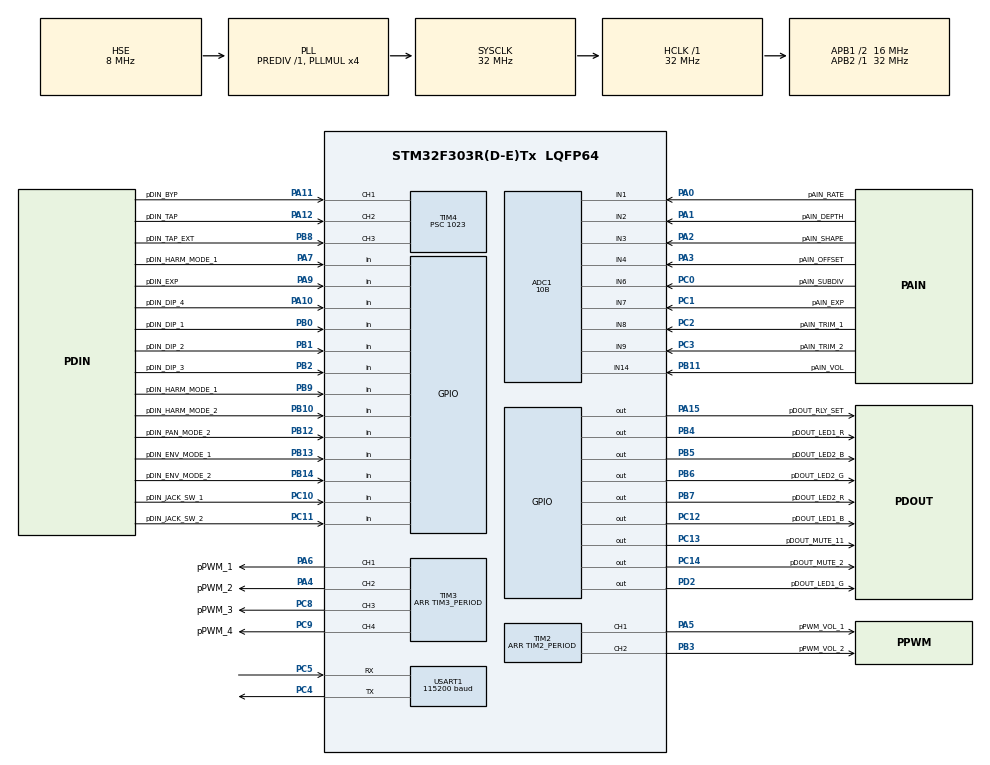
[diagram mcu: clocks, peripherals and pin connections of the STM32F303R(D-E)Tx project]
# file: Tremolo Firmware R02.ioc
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ADC1.AWD1ITMode=ENABLE
ADC1.Channel-0\#ChannelRegularConversion=ADC_CHANNEL_1
ADC1.ClockPrescaler=ADC_CLOCK_SYNC_PCLK_DIV1
ADC1.ContinuousConvMode=ENABLE
ADC1.DMAContinuousRequests=ENABLE
ADC1.EOCSelection=ADC_EOC_SEQ_CONV
ADC1.EnableAnalogWatchDog1=true
ADC1.EnableInjectedConversion=DISABLE
ADC1.ExternalTrigConv=ADC_SOFTWARE_START
ADC1.Mode=ADC_MODE_INDEPENDENT
ADC1.NbrOfConversion=1
ADC1.NbrOfConversionFlag=1
ADC1.Offset-0\#ChannelRegularConversion=0
ADC1.OffsetNumber-0\#ChannelRegularConversion=ADC_OFFSET_NONE
ADC1.Rank-0\#ChannelRegularConversion=1
ADC1.Rank1_Channel=ADC_CHANNEL_1
ADC1.Rank2_Channel=ADC_CHANNEL_1
ADC1.Resolution=ADC_RESOLUTION_10B
ADC1.SamplingTime-0\#ChannelRegularConversion=ADC_SAMPLETIME_1CYCLE_5
ADC1.master=1
Dma.ADC1.0.Direction=DMA_PERIPH_TO_MEMORY
Dma.ADC1.0.Instance=DMA1_Channel1
Dma.ADC1.0.MemDataAlignment=DMA_MDATAALIGN_HALFWORD
Dma.ADC1.0.MemInc=DMA_MINC_ENABLE
Dma.ADC1.0.Mode=DMA_CIRCULAR
Dma.ADC1.0.PeriphDataAlignment=DMA_PDATAALIGN_HALFWORD
Dma.ADC1.0.PeriphInc=DMA_PINC_DISABLE
Dma.ADC1.0.Priority=DMA_PRIORITY_HIGH
Dma.Request0=ADC1
Dma.Request1=TIM8_CH3/UP
Dma.Request2=TIM8_CH4/TRIG/COM
Dma.Request3=TIM4_CH2
Dma.TIM4_CH2.3.Direction=DMA_PERIPH_TO_MEMORY
Dma.TIM4_CH2.3.Instance=DMA1_Channel4
Dma.TIM4_CH2.3.MemDataAlignment=DMA_MDATAALIGN_HALFWORD
Dma.TIM4_CH2.3.MemInc=DMA_MINC_ENABLE
Dma.TIM4_CH2.3.Mode=DMA_CIRCULAR
Dma.TIM4_CH2.3.PeriphDataAlignment=DMA_PDATAALIGN_HALFWORD
Dma.TIM4_CH2.3.PeriphInc=DMA_PINC_DISABLE
Dma.TIM4_CH2.3.Priority=DMA_PRIORITY_MEDIUM
Dma.TIM8_CH3/UP.1.Direction=DMA_MEMORY_TO_PERIPH
Dma.TIM8_CH3/UP.1.Instance=DMA2_Channel1
Dma.TIM8_CH3/UP.1.MemDataAlignment=DMA_MDATAALIGN_HALFWORD
Dma.TIM8_CH3/UP.1.MemInc=DMA_MINC_ENABLE
Dma.TIM8_CH3/UP.1.Mode=DMA_CIRCULAR
Dma.TIM8_CH3/UP.1.PeriphDataAlignment=DMA_PDATAALIGN_HALFWORD
Dma.TIM8_CH3/UP.1.PeriphInc=DMA_PINC_DISABLE
Dma.TIM8_CH3/UP.1.Priority=DMA_PRIORITY_VERY_HIGH
Dma.TIM8_CH4/TRIG/COM.2.Direction=DMA_MEMORY_TO_PERIPH
Dma.TIM8_CH4/TRIG/COM.2.Instance=DMA2_Channel2
Dma.TIM8_CH4/TRIG/COM.2.MemDataAlignment=DMA_MDATAALIGN_HALFWORD
Dma.TIM8_CH4/TRIG/COM.2.MemInc=DMA_MINC_ENABLE
Dma.TIM8_CH4/TRIG/COM.2.Mode=DMA_CIRCULAR
Dma.TIM8_CH4/TRIG/COM.2.PeriphDataAlignment=DMA_PDATAALIGN_HALFWORD
Dma.TIM8_CH4/TRIG/COM.2.PeriphInc=DMA_PINC_DISABLE
Dma.TIM8_CH4/TRIG/COM.2.Priority=DMA_PRIORITY_HIGH
Mcu.Family=STM32F3
Mcu.Name=STM32F303R(D-E)Tx
Mcu.Package=LQFP64
Mcu.UserConstants=TIM2_PERIOD,1023;TIM3_PERIOD,1023
NVIC.DMA1_Channel1_IRQn=true\:0\:0\:false\:false\:true\:false\:true
NVIC.DMA1_Channel4_IRQn=true\:0\:0\:false\:false\:true\:false\:true
NVIC.DMA2_Channel1_IRQn=true\:0\:0\:false\:false\:true\:false\:true
NVIC.DMA2_Channel2_IRQn=true\:0\:0\:false\:false\:true\:false\:true
NVIC.PriorityGroup=NVIC_PRIORITYGROUP_4
NVIC.TIM4_IRQn=true\:0\:0\:false\:false\:true\:true\:true
NVIC.TIM8_UP_IRQn=true\:0\:0\:false\:false\:true\:true\:true
PA0.GPIO_Label=pAIN_RATE
PA0.Mode=IN1-Single-Ended
PA0.Signal=ADC1_IN1
PA1.GPIO_Label=pAIN_DEPTH
PA1.Mode=IN2-Single-Ended
PA1.Signal=ADC1_IN2
PA10.GPIO_Label=pDIN_DIP_4
PA10.GPIO_PuPd=GPIO_PULLUP
PA10.Signal=GPIO_Input
PA11.GPIO_Label=pDIN_BYP
PA11.GPIO_PuPd=GPIO_PULLUP
PA11.Signal=S_TIM4_CH1
PA12.GPIO_Label=pDIN_TAP
PA12.GPIO_PuPd=GPIO_PULLUP
PA12.Signal=S_TIM4_CH2
PA13.Signal=SYS_JTMS-SWDIO
PA14.Signal=SYS_JTCK-SWCLK
PA15.GPIO_Label=pDOUT_RLY_SET
PA15.Signal=GPIO_Output
PA2.GPIO_Label=pAIN_SHAPE
PA2.Mode=IN3-Single-Ended
PA2.Signal=ADC1_IN3
PA3.GPIO_Label=pAIN_OFFSET
PA3.Mode=IN4-Single-Ended
PA3.Signal=ADC1_IN4
PA4.GPIO_Label=pPWM_2
PA4.Signal=S_TIM3_CH2
PA5.GPIO_Label=pPWM_VOL_1
PA5.Signal=S_TIM2_CH1_ETR
PA6.GPIO_Label=pPWM_1
PA6.Signal=S_TIM3_CH1
PA7.GPIO_Label=pDIN_HARM_MODE_1
PA7.GPIO_PuPd=GPIO_PULLUP
PA7.Signal=GPIO_Input
PA9.GPIO_Label=pDIN_EXP
PA9.GPIO_PuPd=GPIO_PULLUP
PA9.Signal=GPIO_Input
PB0.GPIO_Label=pDIN_DIP_1
PB0.GPIO_PuPd=GPIO_PULLUP
PB0.Signal=GPIO_Input
PB1.GPIO_Label=pDIN_DIP_2
PB1.GPIO_PuPd=GPIO_PULLUP
PB1.Signal=GPIO_Input
PB10.GPIO_Label=pDIN_HARM_MODE_2
PB10.GPIO_PuPd=GPIO_PULLUP
PB10.Signal=GPIO_Input
PB11.GPIO_Label=pAIN_VOL
PB11.Mode=IN14-Single-Ended
PB11.Signal=ADC1_IN14
PB12.GPIO_Label=pDIN_PAN_MODE_2
PB12.GPIO_PuPd=GPIO_PULLUP
PB12.Signal=GPIO_Input
PB13.GPIO_Label=pDIN_ENV_MODE_1
PB13.GPIO_PuPd=GPIO_PULLUP
PB13.Signal=GPIO_Input
PB14.GPIO_Label=pDIN_ENV_MODE_2
PB14.GPIO_PuPd=GPIO_PULLUP
PB14.Signal=GPIO_Input
PB2.GPIO_Label=pDIN_DIP_3
PB2.GPIO_PuPd=GPIO_PULLUP
PB2.Signal=GPIO_Input
PB3.GPIO_Label=pPWM_VOL_2
PB3.Signal=S_TIM2_CH2
PB4.GPIO_Label=pDOUT_LED1_R
PB4.Signal=GPIO_Output
PB5.GPIO_Label=pDOUT_LED2_B
PB5.Signal=GPIO_Output
PB6.GPIO_Label=pDOUT_LED2_G
PB6.Signal=GPIO_Output
PB7.GPIO_Label=pDOUT_LED2_R
PB7.Signal=GPIO_Output
PB8.GPIO_Label=pDIN_TAP_EXT
PB8.GPIO_PuPd=GPIO_PULLUP
PB8.Signal=S_TIM4_CH3
PB9.GPIO_Label=pDIN_HARM_MODE_1
PB9.GPIO_PuPd=GPIO_PULLUP
PB9.Signal=GPIO_Input
PC0.GPIO_Label=pAIN_SUBDIV
PC0.Signal=ADCx_IN6
PC1.GPIO_Label=pAIN_EXP
PC1.Signal=ADCx_IN7
PC10.GPIO_Label=pDIN_JACK_SW_1
PC10.GPIO_PuPd=GPIO_PULLUP
PC10.Signal=GPIO_Input
PC11.GPIO_Label=pDIN_JACK_SW_2
PC11.GPIO_PuPd=GPIO_PULLUP
PC11.Signal=GPIO_Input
PC12.GPIO_Label=pDOUT_LED1_B
PC12.Signal=GPIO_Output
PC13.GPIO_Label=pDOUT_MUTE_11
PC13.Signal=GPIO_Output
PC14-OSC32_IN.GPIO_Label=pDOUT_MUTE_2
PC14-OSC32_IN.Signal=GPIO_Output
PC2.GPIO_Label=pAIN_TRIM_1
PC2.Signal=ADCx_IN8
PC3.GPIO_Label=pAIN_TRIM_2
PC3.Signal=ADCx_IN9
PC4.Mode=Asynchronous
PC4.Signal=USART1_TX
PC5.Mode=Asynchronous
PC5.Signal=USART1_RX
PC8.GPIO_Label=pPWM_3
PC8.Signal=S_TIM3_CH3
PC9.GPIO_Label=pPWM_4
PC9.Signal=S_TIM3_CH4
PD2.GPIO_Label=pDOUT_LED1_G
PD2.Signal=GPIO_Output
PF0-OSC_IN.Mode=HSE-External-Oscillator
PF0-OSC_IN.Signal=RCC_OSC_IN
PF1-OSC_OUT.Mode=HSE-External-Oscillator
PF1-OSC_OUT.Signal=RCC_OSC_OUT
ProjectManager.HeapSize=0x200
ProjectManager.StackSize=0x400
ProjectManager.TargetToolchain=STM32CubeIDE
RCC.AHBFreq_Value=32000000
RCC.APB1CLKDivider=RCC_HCLK_DIV2
RCC.APB1Freq_Value=16000000
RCC.APB1TimFreq_Value=32000000
RCC.APB2Freq_Value=32000000
RCC.APB2TimFreq_Value=32000000
RCC.CortexFreq_Value=32000000
RCC.HCLKFreq_Value=32000000
RCC.HSE_VALUE=8000000
RCC.HSI_VALUE=8000000
RCC.LSE_VALUE=32768
RCC.PLLMUL=RCC_PLL_MUL4
RCC.PLLSourceVirtual=RCC_PLLSOURCE_HSE
RCC.SYSCLKFreq_VALUE=32000000
RCC.SYSCLKSourceVirtual=RCC_SYSCLKSOURCE_PLLCLK
RCC.USBFreq_Value=32000000
SH.ADCx_IN6.0=ADC1_IN6,IN6-Single-Ended
SH.ADCx_IN6.1=ADC2_IN6
SH.ADCx_IN7.0=ADC1_IN7,IN7-Single-Ended
SH.ADCx_IN7.1=ADC2_IN7
SH.ADCx_IN8.0=ADC1_IN8,IN8-Single-Ended
SH.ADCx_IN9.0=ADC1_IN9,IN9-Single-Ended
SH.S_TIM2_CH1_ETR.0=TIM2_CH1,PWM Generation1 CH1
SH.S_TIM2_CH2.0=TIM2_CH2,PWM Generation2 CH2
SH.S_TIM3_CH1.0=TIM3_CH1,PWM Generation1 CH1
SH.S_TIM3_CH2.0=TIM3_CH2,PWM Generation2 CH2
SH.S_TIM3_CH3.0=TIM3_CH3,PWM Generation3 CH3
SH.S_TIM3_CH4.0=TIM3_CH4,PWM Generation4 CH4
SH.S_TIM4_CH1.0=TIM4_CH1,Input_Capture1_from_TI1
SH.S_TIM4_CH2.0=TIM4_CH2,Input_Capture2_from_TI2
SH.S_TIM4_CH3.0=TIM4_CH3,Input_Capture3_from_TI3
TIM2.Channel-PWM\ Generation1\ CH1=TIM_CHANNEL_1
TIM2.Channel-PWM\ Generation2\ CH2=TIM_CHANNEL_2
TIM2.Period=TIM2_PERIOD
TIM2.TIM_MasterSlaveMode=TIM_MASTERSLAVEMODE_DISABLE
TIM3.Channel-PWM\ Generation1\ CH1=TIM_CHANNEL_1
TIM3.Channel-PWM\ Generation2\ CH2=TIM_CHANNEL_2
TIM3.Channel-PWM\ Generation3\ CH3=TIM_CHANNEL_3
TIM3.Channel-PWM\ Generation4\ CH4=TIM_CHANNEL_4
TIM3.OCPolarity_2=TIM_OCPOLARITY_LOW
TIM3.OCPolarity_4=TIM_OCPOLARITY_LOW
TIM3.Period=TIM3_PERIOD
TIM4.Channel-Input_Capture1_from_TI1=TIM_CHANNEL_1
TIM4.Channel-Input_Capture2_from_TI2=TIM_CHANNEL_2
TIM4.Channel-Input_Capture3_from_TI3=TIM_CHANNEL_3
TIM4.ICFilter_CH1=15
TIM4.ICFilter_CH2=15
TIM4.ICFilter_CH3=15
TIM4.ICPolarity_CH1=TIM_INPUTCHANNELPOLARITY_FALLING
TIM4.ICPolarity_CH2=TIM_INPUTCHANNELPOLARITY_FALLING
TIM4.ICPolarity_CH3=TIM_INPUTCHANNELPOLARITY_FALLING
TIM4.Prescaler=1023
TIM8.Channel-PWM\ Generation1\ No\ Output=TIM_CHANNEL_1
TIM8.Period=1023
TIM8.RepetitionCounter=511
TIM8.TIM_MasterOutputTrigger=TIM_TRGO_UPDATE
USART1.BaudRate=115200
USART1.Parity=PARITY_NONE
USART1.VirtualMode-Asynchronous=VM_ASYNC
VP_TIM8_VS_no_output1.Mode=PWM Generation1 No Output
board=custom

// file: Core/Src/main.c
/* USER CODE BEGIN Header */
/**
  ******************************************************************************
  * @file           : main.c
  * @brief          : Main program body
  ******************************************************************************
  * @attention
  *
  * <h2><center>&copy; Copyright (c) 2021 STMicroelectronics.
  * All rights reserved.</center></h2>
  *
  * This software component is licensed by ST under BSD 3-Clause license,
  * the "License"; You may not use this file except in compliance with the
  * License. You may obtain a copy of the License at:
  *                        opensource.org/licenses/BSD-3-Clause
  *
  ******************************************************************************
  */
/* USER CODE END Header */
#include "main.h"
#include "adc.h"
#include "dma.h"
#include "tim.h"
#include "usart.h"
#include "gpio.h"

void SystemClock_Config(void);

int main(void)
{

  /* MCU Configuration--------------------------------------------------------*/

  /* Reset of all peripherals, Initializes the Flash interface and the Systick. */
  HAL_Init();

  /* Configure the system clock */
  SystemClock_Config();

  /* Initialize all configured peripherals */
  MX_GPIO_Init();
  MX_ADC1_Init();
  MX_TIM2_Init();
  MX_TIM3_Init();
  MX_DMA_Init();
  MX_USART1_UART_Init();
  MX_TIM4_Init();
  MX_TIM8_Init();
  /* USER CODE BEGIN 2 */

  /* Start DMA conversion of ADC data into buffer of raw readings */
  HAL_ADC_Start_DMA(&hadc1, &ADC_VALUES, 10);

  /* Start TIM8 and enable DMA for wavetable transfer and period change */
  HAL_TIM_OC_Start(&htim8, TIM_CHANNEL_1);
  HAL_DMA_Start_IT(&hdma_tim8_ch3_up, (uint16_t)wavetable_sine, (uint32_t)&(TIM3->CCR1), WAVETABLE_WIDTH);
  HAL_DMA_Start_IT(&hdma_tim8_ch4_trig_com, (uint32_t)wave_period, (uint32_t)&(TIM8->ARR), WAVETABLE_WIDTH);

  /* USER CODE END 2 */

  /* Infinite loop */
  while (1)
  {

  }
}

void SystemClock_Config(void)
{
  RCC_OscInitTypeDef RCC_OscInitStruct = {0};
  RCC_ClkInitTypeDef RCC_ClkInitStruct = {0};
  RCC_PeriphCLKInitTypeDef PeriphClkInit = {0};

  /** Initializes the RCC Oscillators according to the specified parameters
  * in the RCC_OscInitTypeDef structure.
  */
  RCC_OscInitStruct.OscillatorType = RCC_OSCILLATORTYPE_HSE;
  RCC_OscInitStruct.HSEState = RCC_HSE_ON;
  RCC_OscInitStruct.HSIState = RCC_HSI_ON;
  RCC_OscInitStruct.PLL.PLLState = RCC_PLL_ON;
  RCC_OscInitStruct.PLL.PLLSource = RCC_PLLSOURCE_HSE;
  RCC_OscInitStruct.PLL.PLLMUL = RCC_PLL_MUL4;
  RCC_OscInitStruct.PLL.PREDIV = RCC_PREDIV_DIV1;
  if (HAL_RCC_OscConfig(&RCC_OscInitStruct) != HAL_OK)
  {
    Error_Handler();
  }
  /** Initializes the CPU, AHB and APB buses clocks
  */
  RCC_ClkInitStruct.ClockType = RCC_CLOCKTYPE_HCLK|RCC_CLOCKTYPE_SYSCLK
                              |RCC_CLOCKTYPE_PCLK1|RCC_CLOCKTYPE_PCLK2;
  RCC_ClkInitStruct.SYSCLKSource = RCC_SYSCLKSOURCE_PLLCLK;
  RCC_ClkInitStruct.AHBCLKDivider = RCC_SYSCLK_DIV1;
  RCC_ClkInitStruct.APB1CLKDivider = RCC_HCLK_DIV2;
  RCC_ClkInitStruct.APB2CLKDivider = RCC_HCLK_DIV1;

  if (HAL_RCC_ClockConfig(&RCC_ClkInitStruct, FLASH_LATENCY_1) != HAL_OK)
  {
    Error_Handler();
  }
  PeriphClkInit.PeriphClockSelection = RCC_PERIPHCLK_USART1|RCC_PERIPHCLK_TIM8
                              |RCC_PERIPHCLK_TIM2|RCC_PERIPHCLK_TIM34;
  PeriphClkInit.Usart1ClockSelection = RCC_USART1CLKSOURCE_PCLK2;
  PeriphClkInit.Tim8ClockSelection = RCC_TIM8CLK_HCLK;
  PeriphClkInit.Tim2ClockSelection = RCC_TIM2CLK_HCLK;
  PeriphClkInit.Tim34ClockSelection = RCC_TIM34CLK_HCLK;
  if (HAL_RCCEx_PeriphCLKConfig(&PeriphClkInit) != HAL_OK)
  {
    Error_Handler();
  }
}

void Error_Handler(void)
{
  __disable_irq();
  while (1)
  {
  }
}

/************************ (C) COPYRIGHT STMicroelectronics *****END OF FILE****/
